# STM32MP25_CM33 register map
File version: 1.3
CPU: CM33 r0p1, little endian, MPU, FPU, vendor SysTick, 8 interrupt priority bits
Registers are 32-bit, read-write, reset 0x0 unless marked. A register's access mark holds for its fields unless they carry their own. Offsets are from the block's base; [hi:lo] are bit positions; {n}, {i} and the like mark numbered series.

## RNG — RNG address block description
Base 0x42020000
Same registers: RNG_S 0x52020000
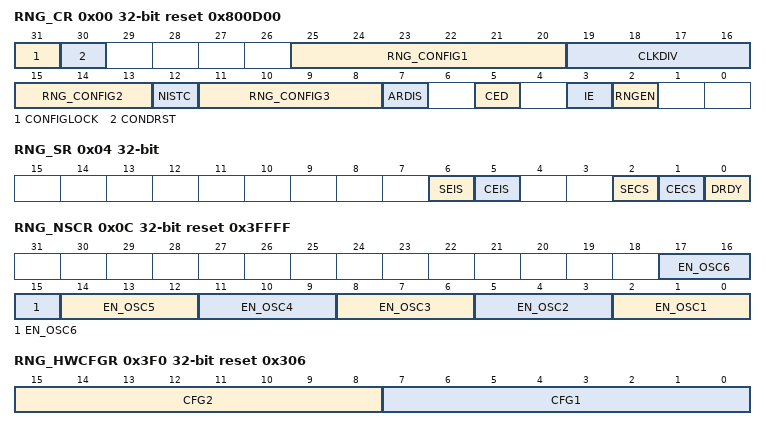
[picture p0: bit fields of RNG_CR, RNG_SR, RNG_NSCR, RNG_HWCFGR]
0x00 RNG_CR reset 0x800D00 — RNG control register
  [31] CONFIGLOCK — RNG Config lock Once set, this bit can only be cleared when RNG is reset (set once bit).
    0=Writes to the RNG_NSCR, RNG_HTCR and RNG_CR configuration bits [29:4] are allowed; 1=Writes to the RNG_NSCR, RNG_HTCR and RNG_CR configuration bits [29:4] are ignored until the next RNG reset
  [30] CONDRST — Conditioning soft reset Write 1 and then write 0 to reset the conditioning logic, clear all the FIFOs and start a new RNG initialization process, with RNG_SR cleared. Registers RNG_CR, RNG_NSCR and RNG_HTCR are not changed by CONDRST. This bit must be set to 1 in the same access that set any configuration bits [29:4]. In other words, when CONDRST bit is set to 1 correct configuration in bits [29:4] must also be written. When CONDRST is set to 0 by the software, its value goes to 0 when the reset process is done. It takes about 2 AHB clock cycles + 2 RNG clock cycles.
  [25:20] RNG_CONFIG1 — RNG configuration 1 Reserved to the RNG configuration (bit field 1). Must be initialized using the recommended value documented in Section57.6: RNG entropy source validation. Writing any bit of RNG_CONFIG1 is taken into account only if the CONDRST bit is set to 1 in the same access, while CONFIGLOCK remains at 0. Writing to this bit is ignored if CONFIGLOCK=1.
  [19:16] CLKDIV — Clock divider factor This value used to configure an internal programmable divider (from 1 to 16) acting on the incoming RNG clock. These bits can be written only when the core is disabled (RNGEN=0). ... Writing these bits is taken into account only if the CONDRST bit is set to 1 in the same access, while CONFIGLOCK remains at 0. Writing to this bit is ignored if CONFIGLOCK=1.
    0=internal RNG clock after divider is similar to incoming RNG clock; 1=two RNG clock cycles per internal RNG clock; 2=2sup2/sup (= 4) RNG clock cycles per internal RNG clock; 15=2sup15/sup RNG clock cycles per internal clock (for example. an incoming 48MHz RNG clock becomes a 1.5kHz internal RNG clock)
  [15:13] RNG_CONFIG2 — RNG configuration 2 Reserved to the RNG configuration (bit field 2). Bit 13 can be set when RNG power consumption is critical. See Section57.3.8: RNG low-power use. Refer to the RNG_CONFIG1 bit field for details.
  [12] NISTC — NIST custom two conditioning loops are performed and 256 bits of noise source are used. Writing this bit is taken into account only if CONDRST bit is set to 1 in the same access, while CONFIGLOCK remains at 0. Writing to this bit is ignored if CONFIGLOCK=1.
    0=Hardware default values for NIST compliant RNG. In this configuration per 128-bit output; 1=Custom values for NIST compliant RNG. See Section57.6: RNG entropy source validation for proposed configuration.
  [11:8] RNG_CONFIG3 — RNG configuration 3 Reserved to the RNG configuration (bit field 3). Refer to RNG_CONFIG1 bit field for details. If the NISTC bit is cleared in this register RNG_CONFIG3 bit field values are ignored by RNG.
  [7] ARDIS — Auto reset disable Set this bit to deactivate the auto-reset feature. Keeping the auto-reset enabled (automatic clearance of the SECS bit) simplifies the management of noise source errors, as described in Section57.3.7: Error management. Writing this bit is taken into account only if CONDRST bit is set to 1 in the same access, while CONFIGLOCK remains at 0. Writing to this bit is ignored if CONFIGLOCK=1.
    0=Auto-reset enabled; 1=Auto-reset disabled
  [5] CED — Clock error detection The clock error detection cannot be enabled nor disabled on-the-fly when the RNG is enabled, that is to enable or disable CED, the RNG must be disabled. Writing this bit is taken into account only if the CONDRST bit is set to 1 in the same access, while CONFIGLOCK remains at 0. Writing to this bit is ignored if CONFIGLOCK=1.
    0=Clock error detection enabled; 1=Clock error detection is disabled
  [3] IE — Interrupt enable
    0=RNG interrupt is disabled; 1=RNG interrupt is enabled. An interrupt is pending as soon as the DRDY, SEIS, or CEIS is set in the RNG_SR register.
  [2] RNGEN — True random number generator enable
    0=True random number generator is disabled. Analog noise sources are powered off and logic clocked by the RNG clock is gated.; 1=True random number generator is enabled
0x04 RNG_SR — RNG status register
  [6] SEIS — Seed error interrupt status This bit is set at the same time as SECS. It is cleared by writing 0 (unless CONDRST is used). Writing 1 has no effect. An interrupt is pending if IE = 1 in the RNG_CR register.
    0=No faulty sequence detected; 1=At least one faulty sequence is detected. See SECS bit description for details.
  [5] CEIS — Clock error interrupt status This bit is set at the same time as CECS. It is cleared by writing 0. Writing 1 has no effect. An interrupt is pending if IE = 1 in the RNG_CR register.
    0=The RNG clock is correct (fsubRNGCLK/sub fsubHCLK/sub/32); 1=The RNG clock before the internal divider is detected too slow (fsubRNGCLK/sub fsubHCLK/sub/32)
  [2] SECS ro — Seed error current status Runtime repetition count test failed (noise source has provided more than 24 consecutive bits at a constant value 0 or 1, or more than 32 consecutive occurrence of two bits patterns 01 or 10) Startup or continuous adaptive proportion test on noise source failed. Startup post-processing/conditioning sanity check failed.
    0=No faulty sequence has currently been detected. If the SEIS bit is set, this means that a faulty sequence was detected and the situation has been recovered.; 1=At least one of the following faulty sequences has been detected:
  [1] CECS ro — Clock error current status Note: CECS bit is valid only if the CED bit in the RNG_CR register is set to 0.
    0=The RNG clock is correct (fsubRNGCLK/sub fsubHCLK/sub/32). If the CEIS bit is set, this means that a slow clock was detected and the situation has been recovered.; 1=The RNG clock is too slow (fsubRNGCLK/sub fsubHCLK/sub/32)
  [0] DRDY ro — Data ready Once the output buffer becomes empty (after reading the RNG_DR register), this bit returns to 0 until a new random value is generated. Note: The DRDY bit can rise when the peripheral is disabled (RNGEN=0 in the RNG_CR register). If IE=1 in the RNG_CR register, an interrupt is generated when DRDY=1.
    0=The RNG_DR register is not yet valid, no random data is available; 1=The RNG_DR register contains valid random data
0x08 RNG_DR ro — RNG data register
  [31:0] RNDATA — Random data 32-bit random data, which are valid when DRDY=1. When DRDY=0, the RNDATA value iszero. When DRDY is set, it is recommended to always verify that RNG_DR is different from zero. The zero value means that a seed error occurred between RNG_SR polling and RND_DR output reading (a rare event).
0x0C RNG_NSCR reset 0x3FFFF — RNG noise source control register
  [3n-1:3n-3] EN_OSC{n} (n=1..6) — Each bit drives one oscillator enable signal input of instance number {n}, gated with the RNGEN bit in RNG_CR (set bit to enable the oscillator). Bit is ignored otherwise.
0x10 RNG_HTCR reset 0x72AC — RNG health test control register
  [31:0] HTCFG — health test configuration This configuration is used by RNG to configure the health tests. See Section57.6: RNG entropy source validation for the recommended value. Note: The RNG behavior, including the read to this register, is not guaranteed if a different value from the recommended value is written.
0x3F0 RNG_HWCFGR ro reset 0x306 — RNG hardware configuration register
  [15:8] CFG2 — Hardware generic 2 This bit field returns the number of RNG buses (rngbus_nb).
  [7:0] CFG1 — Hardware generic 1 This field returns the triple_oscillator_nb generic value (0x6).
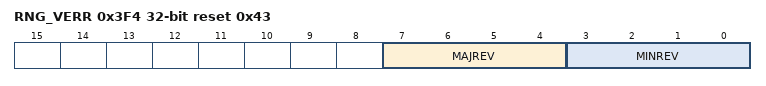
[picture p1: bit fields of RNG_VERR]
0x3F4 RNG_VERR ro reset 0x43 — RNG version register
  [7:4] MAJREV — RNG major revision
  [3:0] MINREV — RNG minor revision
0x3F8 RNG_IPIDR ro reset 0x170041 — RNG identification register
  [31:0] ID — RNG identification code
0x3FC RNG_SIDR ro reset 0xA3C5DD01 — RNG size identification register
  [31:0] SID — RNG size identification code Bits[31:8] = 0xA3C5DD (fixed code) Bits[7:0] = 0x01 (1 Kbyte address decoding)
